VERSION "golf4_min"

NS_ :

BS_:

BU_: ECU DASH

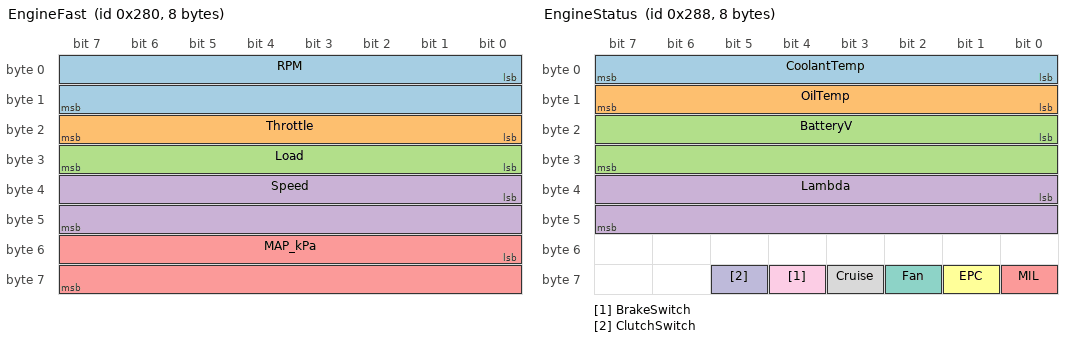
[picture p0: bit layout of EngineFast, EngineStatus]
BO_ 640 EngineFast: 8 ECU
 SG_ RPM : 0|16@1+ (0.25,0) [0|8000] "rpm" DASH
 SG_ Throttle : 16|8@1+ (0.5,0) [0|100] "%" DASH
 SG_ Load : 24|8@1+ (0.5,0) [0|100] "%" DASH
 SG_ Speed : 32|16@1+ (0.1,0) [0|300] "kmh" DASH
 SG_ MAP_kPa : 48|16@1+ (0.1,0) [0|300] "kPa" DASH

BO_ 648 EngineStatus: 8 ECU
 SG_ CoolantTemp : 0|8@1- (1,40) [-40|215] "degC" DASH
 SG_ OilTemp : 8|8@1- (1,40) [-40|215] "degC" DASH
 SG_ BatteryV : 16|16@1+ (0.01,0) [0|20] "V" DASH
 SG_ Lambda : 32|16@1+ (0.001,0) [0|2] "" DASH
 SG_ MIL : 56|1@1+ (1,0) [0|1] "" DASH
 SG_ EPC : 57|1@1+ (1,0) [0|1] "" DASH
 SG_ Fan : 58|1@1+ (1,0) [0|1] "" DASH
 SG_ Cruise : 59|1@1+ (1,0) [0|1] "" DASH
 SG_ BrakeSwitch : 60|1@1+ (1,0) [0|1] "" DASH
 SG_ ClutchSwitch : 61|1@1+ (1,0) [0|1] "" DASH
